# SN32F100 register map
Vendor: SONiX Technology Co., Ltd.; Series: SN32F100; File version: 1.3
CPU: CM0 r0p0, little endian, no MPU, no FPU, 2 interrupt priority bits
Registers are 32-bit, read-write, reset 0x0 unless marked. A register's access mark holds for its fields unless they carry their own. Offsets are from the block's base; [hi:lo] are bit positions.

## SN_SSP0 — SSP0
Base 0x4001C000
Same registers: SN_SSP1 0x40058000
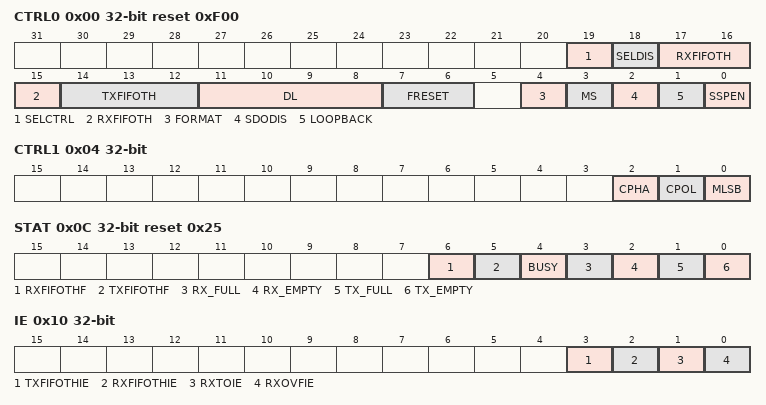
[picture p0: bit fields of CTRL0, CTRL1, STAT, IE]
0x00 CTRL0 reset 0xF00 — Offset:0x00 SSPn Control Register 0
  [19] SELCTRL — Source for SEL pin
    0=SEL-Low (SEL pin is low level.); 1=SEL-High (SEL pin is high level.)
  [18] SELDIS — Auto-SEL disable bit
    0=Enable Auto-SEL flow control; 1=Disable Auto-SEL flow control
  [17:15] RXFIFOTH — Rx FIFO Threshold level
    0=000b (Rx FIFO threshold level is 0); 1=001b (Rx FIFO threshold level is 1); 2=010b (Rx FIFO threshold level is 2); 3=011b (Rx FIFO threshold level is 3); 4=100b (Rx FIFO threshold level is 4); 5=101b (Rx FIFO threshold level is 5); 6=110b (Rx FIFO threshold level is 6); 7=111b (Rx FIFO threshold level is 7)
  [14:12] TXFIFOTH — TX FIFO Threshold level
    0=000b (TX FIFO threshold level is 0); 1=001b (TX FIFO threshold level is 1); 2=010b (TX FIFO threshold level is 2); 3=011b (TX FIFO threshold level is 3); 4=100b (TX FIFO threshold level is 4); 5=101b (TX FIFO threshold level is 5); 6=110b (TX FIFO threshold level is 6); 7=111b (TX FIFO threshold level is 7)
  [11:8] DL — Data length = DL[3:0]+1
    2=0010b (Data length=3); 3=0011b (Data length=4); 4=0100b (Data length=5); 5=0101b (Data length=6); 6=0110b (Data length=7); 7=0111b (Data length=8); 8=1000b (Data length=9); 9=1001b (Data length=10); 10=1010b (Data length=11); 11=1011b (Data length=12); 12=1100b (Data length=13); 13=1101b (Data length=14); 14=1110b (Data length=15); 15=1111b (Data length=16)
  [7:6] FRESET wo — SSP FSM and FIFO Reset
    0=00b (No effect); 3=11b (Reset FSM and FIFO)
  [4] FORMAT — Interface format
    0=SPI; 1=SSI
  [3] MS — Master/Slave selection
    0=Master (Act as Master); 1=Slave (Act as Slave)
  [2] SDODIS — Slave data out disable
    0=Enable slave data out; 1=Disble (Diable slave data out (MISO=0))
  [1] LOOPBACK — Loopback mode enable
    0=Disable loopback mode; 1=Enable loopback mode
  [0] SSPEN — SSP enable
    0=Disable SSP; 1=Enable SSP
0x04 CTRL1 — Offset:0x04 SSPn Control Register 1
  [2] CPHA — Clock phase of edge sampling
    0=The 1st bit is fixed already, and SCK 1st edge is to receive/transmit data; 1=SCK 1st edge is for data transition, and receive/transmit data at 2nd edge
  [1] CPOL — Clock priority selection
    0=Low (SCK idles at low level); 1=High (SCK idles at high level)
  [0] MLSB — MSB/LSB seletion
    0=MSB (MSB transmit first); 1=LSB (LSB transmit first)
0x08 CLKDIV — Offset:0x08 SSPn Clock Divider Register
  [7:0] DIV — SSPn SCK=SSPn_PCLK/(2*DIV+2)
0x0C STAT ro reset 0x25 — Offset:0x0C SSPn Status Register
  [6] RXFIFOTHF — RX FIFO threshold flag
    0=RX FIFO is less equal than RXFIFOTH (Data in RX FIFO is less equal than RXFIFOTH); 1=RX FIFO is larger than RXFIFOTH (Data in RX FIFO is larger than RXFIFOTH)
  [5] TXFIFOTHF — TX FIFO threshold flag
    0=TX FIFO is larger than TXFIFOTH (Data in TX FIFO is larger than TXFIFOTH); 1=TX FIFO is less equal than TXFIFOTH (Data in TX FIFO is less equal than TXFIFOTH)
  [4] BUSY — Busy flag
    0=Idle (SSPn is idle); 1=Busy (SSPn is transfering)
  [3] RX_FULL — RX FIFO full flag
    0=RX FIFO is not full; 1=RX FIFO is full
  [2] RX_EMPTY — RX FIFO empty flag
    0=RX FIFO is not empty; 1=RX FIFO is empty
  [1] TX_FULL — TX FIFO full flag
    0=TX FIFO is not full; 1=TX FIFO is full
  [0] TX_EMPTY — TX FIFO empty flag
    0=TX FIFO is not empty; 1=TX FIFO is empty
0x10 IE — Offset:0x10 SSPn Interrupt Enable Register
  [3] TXFIFOTHIE — TX FIFO threshold interrupt enable
    0=Disable; 1=Enable
  [2] RXFIFOTHIE — RX FIFO threshold interrupt enable
    0=Disable; 1=Enable
  [1] RXTOIE — RX time-out interrupt enable
    0=Disable RX time-out interrupt; 1=Enable RX time-out interrupt
  [0] RXOVFIE — RX FIFO overflow interrupt enable
    0=Disable RX FIFO overflow interrupt; 1=Enable RX FIFO overflow interrupt
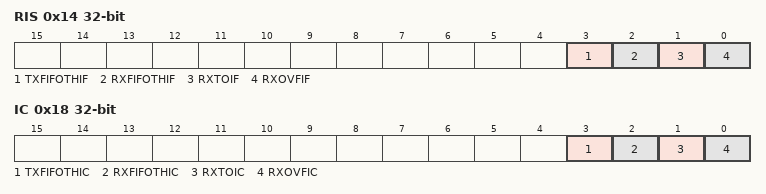
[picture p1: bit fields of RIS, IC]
0x14 RIS ro — Offset:0x14 SSPn Raw Interrupt Status Register
  [3] TXFIFOTHIF — TX FIFO threshold interrupt flag
    0=No TXFIFOTH interrupt; 1=Met TXFIFOTH interrupt requirements (TX FIFO threshold is triggered when TXFIFOTHIE=1)
  [2] RXFIFOTHIF — RX FIFO threshold interrupt flag
    0=No (No RXFIFOTH interrupt); 1=Met RXFIFOTH interrupt requirements (RX FIFO threshold is triggered when RXFIFOTHIE=1)
  [1] RXTOIF — RX time-out interrupt flag
    0=No RXTO interrupt; 1=Met RXTO interrupt requirements (RXTO interrupt is triggered when RXTOIE=1)
  [0] RXOVFIF — RX FIFO overflow interrupt flag
    0=No RXOVF interrupt; 1=Met RXOVF interrupt requirements (RXOVF interrupt is triggered when RXOVFIE=1)
0x18 IC wo — Offset:0x18 SSPn Interrupt Clear Register
  [3] TXFIFOTHIC — TX Interrupt flag Clear
    0=No effect; 1=Clear TXFIFOTH flag
  [2] RXFIFOTHIC — RX Interrupt flag Clear
    0=No effect; 1=Clear RXFIFOTH flag
  [1] RXTOIC — RX time-out interrupt flag clear
    0=No effect; 1=Clear RXTO flag
  [0] RXOVFIC — RX FIFO overflow flag clear
    0=No effect; 1=Clear RXOVF flag
0x1C DATA — Offset:0x1C SSPn Data Register
  [15:0] Data
0x20 DF — Offset:0x20 SPIn Data Fetch Register
  [0] DF — SPI data fetch control bit
    0=Disable; 1=Enable when SCKn frequency is higher than 6MHz
